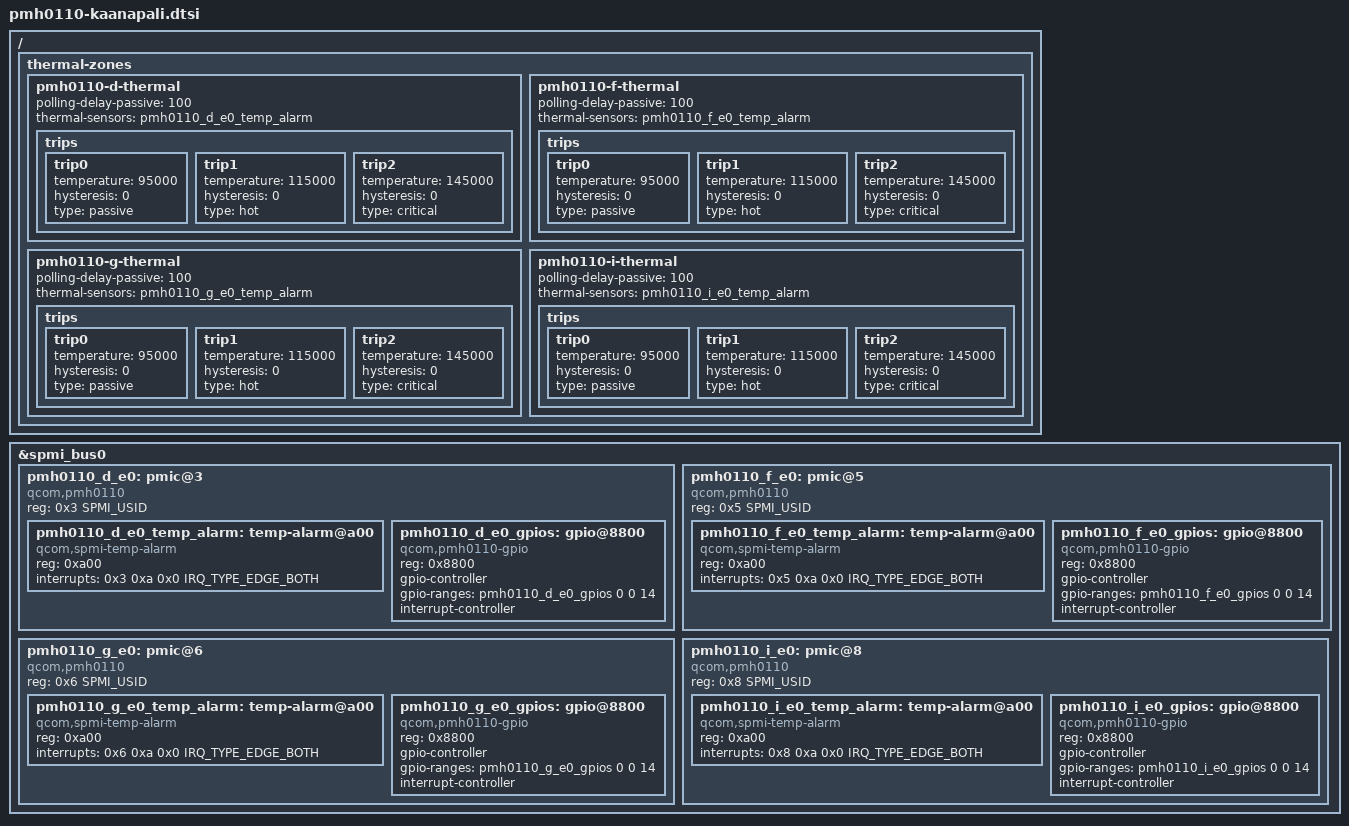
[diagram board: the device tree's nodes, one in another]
// SPDX-License-Identifier: BSD-3-Clause-Clear
/*
 * Copyright (c) Qualcomm Technologies, Inc. and/or its subsidiaries.
 */

#include <dt-bindings/interrupt-controller/irq.h>
#include <dt-bindings/spmi/spmi.h>

/ {
	thermal-zones {
		pmh0110-d-thermal {
			polling-delay-passive = <100>;

			thermal-sensors = <&pmh0110_d_e0_temp_alarm>;

			trips {
				trip0 {
					temperature = <95000>;
					hysteresis = <0>;
					type = "passive";
				};

				trip1 {
					temperature = <115000>;
					hysteresis = <0>;
					type = "hot";
				};

				trip2 {
					temperature = <145000>;
					hysteresis = <0>;
					type = "critical";
				};
			};
		};

		pmh0110-f-thermal {
			polling-delay-passive = <100>;

			thermal-sensors = <&pmh0110_f_e0_temp_alarm>;

			trips {
				trip0 {
					temperature = <95000>;
					hysteresis = <0>;
					type = "passive";
				};

				trip1 {
					temperature = <115000>;
					hysteresis = <0>;
					type = "hot";
				};

				trip2 {
					temperature = <145000>;
					hysteresis = <0>;
					type = "critical";
				};
			};
		};

		pmh0110-g-thermal {
			polling-delay-passive = <100>;

			thermal-sensors = <&pmh0110_g_e0_temp_alarm>;

			trips {
				trip0 {
					temperature = <95000>;
					hysteresis = <0>;
					type = "passive";
				};

				trip1 {
					temperature = <115000>;
					hysteresis = <0>;
					type = "hot";
				};

				trip2 {
					temperature = <145000>;
					hysteresis = <0>;
					type = "critical";
				};
			};
		};

		pmh0110-i-thermal {
			polling-delay-passive = <100>;

			thermal-sensors = <&pmh0110_i_e0_temp_alarm>;

			trips {
				trip0 {
					temperature = <95000>;
					hysteresis = <0>;
					type = "passive";
				};

				trip1 {
					temperature = <115000>;
					hysteresis = <0>;
					type = "hot";
				};

				trip2 {
					temperature = <145000>;
					hysteresis = <0>;
					type = "critical";
				};
			};
		};
	};
};

&spmi_bus0 {
	pmh0110_d_e0: pmic@3 {
		compatible = "qcom,pmh0110", "qcom,spmi-pmic";
		reg = <0x3 SPMI_USID>;
		#address-cells = <1>;
		#size-cells = <0>;

		pmh0110_d_e0_temp_alarm: temp-alarm@a00 {
			compatible = "qcom,spmi-temp-alarm";
			reg = <0xa00>;
			interrupts = <0x3 0xa 0x0 IRQ_TYPE_EDGE_BOTH>;
			#thermal-sensor-cells = <0>;
		};

		pmh0110_d_e0_gpios: gpio@8800 {
			compatible = "qcom,pmh0110-gpio", "qcom,spmi-gpio";
			reg = <0x8800>;
			gpio-controller;
			gpio-ranges = <&pmh0110_d_e0_gpios 0 0 14>;
			#gpio-cells = <2>;
			interrupt-controller;
			#interrupt-cells = <2>;
		};
	};

	pmh0110_f_e0: pmic@5 {
		compatible = "qcom,pmh0110", "qcom,spmi-pmic";
		reg = <0x5 SPMI_USID>;
		#address-cells = <1>;
		#size-cells = <0>;

		pmh0110_f_e0_temp_alarm: temp-alarm@a00 {
			compatible = "qcom,spmi-temp-alarm";
			reg = <0xa00>;
			interrupts = <0x5 0xa 0x0 IRQ_TYPE_EDGE_BOTH>;
			#thermal-sensor-cells = <0>;
		};

		pmh0110_f_e0_gpios: gpio@8800 {
			compatible = "qcom,pmh0110-gpio", "qcom,spmi-gpio";
			reg = <0x8800>;
			gpio-controller;
			gpio-ranges = <&pmh0110_f_e0_gpios 0 0 14>;
			#gpio-cells = <2>;
			interrupt-controller;
			#interrupt-cells = <2>;
		};
	};

	pmh0110_g_e0: pmic@6 {
		compatible = "qcom,pmh0110", "qcom,spmi-pmic";
		reg = <0x6 SPMI_USID>;
		#address-cells = <1>;
		#size-cells = <0>;

		pmh0110_g_e0_temp_alarm: temp-alarm@a00 {
			compatible = "qcom,spmi-temp-alarm";
			reg = <0xa00>;
			interrupts = <0x6 0xa 0x0 IRQ_TYPE_EDGE_BOTH>;
			#thermal-sensor-cells = <0>;
		};

		pmh0110_g_e0_gpios: gpio@8800 {
			compatible = "qcom,pmh0110-gpio", "qcom,spmi-gpio";
			reg = <0x8800>;
			gpio-controller;
			gpio-ranges = <&pmh0110_g_e0_gpios 0 0 14>;
			#gpio-cells = <2>;
			interrupt-controller;
			#interrupt-cells = <2>;
		};
	};

	pmh0110_i_e0: pmic@8 {
		compatible = "qcom,pmh0110", "qcom,spmi-pmic";
		reg = <0x8 SPMI_USID>;
		#address-cells = <1>;
		#size-cells = <0>;

		pmh0110_i_e0_temp_alarm: temp-alarm@a00 {
			compatible = "qcom,spmi-temp-alarm";
			reg = <0xa00>;
			interrupts = <0x8 0xa 0x0 IRQ_TYPE_EDGE_BOTH>;
			#thermal-sensor-cells = <0>;
		};

		pmh0110_i_e0_gpios: gpio@8800 {
			compatible = "qcom,pmh0110-gpio", "qcom,spmi-gpio";
			reg = <0x8800>;
			gpio-controller;
			gpio-ranges = <&pmh0110_i_e0_gpios 0 0 14>;
			#gpio-cells = <2>;
			interrupt-controller;
			#interrupt-cells = <2>;
		};
	};
};
